AUTOSAR XML (schema 4-2-2)
package /STELLANTIS/EPT/SASWCs
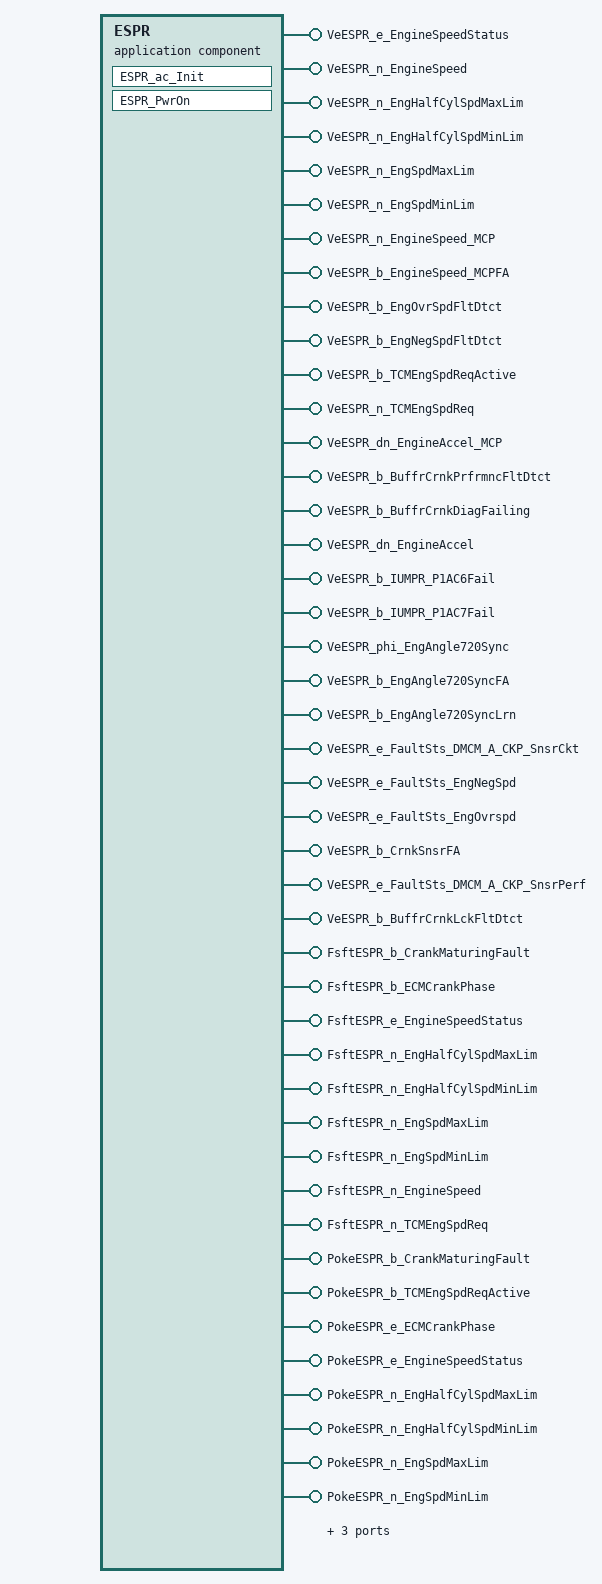
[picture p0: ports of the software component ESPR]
  application sw component type ESPR
    47 x provide port:
      VeESPR_e_EngineSpeedStatus: nonqueued-sender-com-spec{data-element=Value, init-value=CeESPR_e_EngSpdNormal}, provided-interface=VeESPR_e_EngineSpeedStatus
      VeESPR_n_EngineSpeed: nonqueued-sender-com-spec{data-element=Value, init-value=0}, provided-interface=VeESPR_n_EngineSpeed
      VeESPR_n_EngHalfCylSpdMaxLim: nonqueued-sender-com-spec{data-element=Value, init-value=0}, provided-interface=VeESPR_n_EngHalfCylSpdMaxLim
      VeESPR_n_EngHalfCylSpdMinLim: nonqueued-sender-com-spec{data-element=Value, init-value=0}, provided-interface=VeESPR_n_EngHalfCylSpdMinLim
      VeESPR_n_EngSpdMaxLim: nonqueued-sender-com-spec{data-element=Value, init-value=0}, provided-interface=VeESPR_n_EngSpdMaxLim
      VeESPR_n_EngSpdMinLim: nonqueued-sender-com-spec{data-element=Value, init-value=0}, provided-interface=VeESPR_n_EngSpdMinLim
      VeESPR_n_EngineSpeed_MCP: nonqueued-sender-com-spec{data-element=Value, init-value=0}, provided-interface=VeESPR_n_EngineSpeed_MCP
      VeESPR_b_EngineSpeed_MCPFA: nonqueued-sender-com-spec{data-element=Value, init-value=0}, provided-interface=VeESPR_b_EngineSpeed_MCPFA
      VeESPR_b_EngOvrSpdFltDtct: nonqueued-sender-com-spec{data-element=Value, init-value=0}, provided-interface=VeESPR_b_EngOvrSpdFltDtct
      VeESPR_b_EngNegSpdFltDtct: nonqueued-sender-com-spec{data-element=Value, init-value=0}, provided-interface=VeESPR_b_EngNegSpdFltDtct
      VeESPR_b_TCMEngSpdReqActive: nonqueued-sender-com-spec{data-element=Value, init-value=0}, provided-interface=VeESPR_b_TCMEngSpdReqActive
      VeESPR_n_TCMEngSpdReq: nonqueued-sender-com-spec{data-element=Value, init-value=0}, provided-interface=VeESPR_n_TCMEngSpdReq
      VeESPR_dn_EngineAccel_MCP: nonqueued-sender-com-spec{data-element=Value, init-value=0}, provided-interface=VeESPR_dn_EngineAccel_MCP
      VeESPR_b_BuffrCrnkPrfrmncFltDtct: nonqueued-sender-com-spec{data-element=Value, init-value=0}, provided-interface=VeESPR_b_BuffrCrnkPrfrmncFltDtct
      VeESPR_b_BuffrCrnkDiagFailing: nonqueued-sender-com-spec{data-element=Value, init-value=0}, provided-interface=VeESPR_b_BuffrCrnkDiagFailing
      VeESPR_dn_EngineAccel: nonqueued-sender-com-spec{data-element=Value, init-value=0}, provided-interface=VeESPR_dn_EngineAccel
      VeESPR_b_IUMPR_P1AC6Fail: nonqueued-sender-com-spec{data-element=Value, init-value=0}, provided-interface=VeESPR_b_IUMPR_P1AC6Fail
      VeESPR_b_IUMPR_P1AC7Fail: nonqueued-sender-com-spec{data-element=Value, init-value=0}, provided-interface=VeESPR_b_IUMPR_P1AC7Fail
      VeESPR_phi_EngAngle720Sync: nonqueued-sender-com-spec{data-element=Value, init-value=0}, provided-interface=VeESPR_phi_EngAngle720Sync
      VeESPR_b_EngAngle720SyncFA: nonqueued-sender-com-spec{data-element=Value, init-value=0}, provided-interface=VeESPR_b_EngAngle720SyncFA
      VeESPR_b_EngAngle720SyncLrn: nonqueued-sender-com-spec{data-element=Value, init-value=0}, provided-interface=VeESPR_b_EngAngle720SyncLrn
      VeESPR_e_FaultSts_DMCM_A_CKP_SnsrCkt: nonqueued-sender-com-spec{data-element=Value, init-value=CeDFIB_e_Init}, provided-interface=VeESPR_e_FaultSts_DMCM_A_CKP_SnsrCkt
      VeESPR_e_FaultSts_EngNegSpd: nonqueued-sender-com-spec{data-element=Value, init-value=CeDFIB_e_Init}, provided-interface=VeESPR_e_FaultSts_EngNegSpd
      VeESPR_e_FaultSts_EngOvrspd: nonqueued-sender-com-spec{data-element=Value, init-value=CeDFIB_e_Init}, provided-interface=VeESPR_e_FaultSts_EngOvrspd
      VeESPR_b_CrnkSnsrFA: nonqueued-sender-com-spec{data-element=Value, init-value=0}, provided-interface=VeESPR_b_CrnkSnsrFA
      VeESPR_e_FaultSts_DMCM_A_CKP_SnsrPerf: nonqueued-sender-com-spec{data-element=Value, init-value=CeDFIB_e_Init}, provided-interface=VeESPR_e_FaultSts_DMCM_A_CKP_SnsrPerf
      VeESPR_b_BuffrCrnkLckFltDtct: nonqueued-sender-com-spec{data-element=Value, init-value=0}, provided-interface=VeESPR_b_BuffrCrnkLckFltDtct
      FsftESPR_b_CrankMaturingFault: server-com-spec=FsftESPR_b_CrankMaturingFault, provided-interface=FsftESPR_b_CrankMaturingFault
      FsftESPR_b_ECMCrankPhase: server-com-spec=FsftESPR_b_ECMCrankPhase, provided-interface=FsftESPR_b_ECMCrankPhase
      FsftESPR_e_EngineSpeedStatus: server-com-spec=FsftESPR_e_EngineSpeedStatus, provided-interface=FsftESPR_e_EngineSpeedStatus
      FsftESPR_n_EngHalfCylSpdMaxLim: server-com-spec=FsftESPR_n_EngHalfCylSpdMaxLim, provided-interface=FsftESPR_n_EngHalfCylSpdMaxLim
      FsftESPR_n_EngHalfCylSpdMinLim: server-com-spec=FsftESPR_n_EngHalfCylSpdMinLim, provided-interface=FsftESPR_n_EngHalfCylSpdMinLim
      FsftESPR_n_EngSpdMaxLim: server-com-spec=FsftESPR_n_EngSpdMaxLim, provided-interface=FsftESPR_n_EngSpdMaxLim
      FsftESPR_n_EngSpdMinLim: server-com-spec=FsftESPR_n_EngSpdMinLim, provided-interface=FsftESPR_n_EngSpdMinLim
      FsftESPR_n_EngineSpeed: server-com-spec=FsftESPR_n_EngineSpeed, provided-interface=FsftESPR_n_EngineSpeed
      FsftESPR_n_TCMEngSpdReq: server-com-spec=FsftESPR_n_TCMEngSpdReq, provided-interface=FsftESPR_n_TCMEngSpdReq
      PokeESPR_b_CrankMaturingFault: server-com-spec{operation=PokeESPR_b_CrankMaturingFault, queue-length=1}, provided-interface=PokeESPR_b_CrankMaturingFault
      PokeESPR_b_TCMEngSpdReqActive: server-com-spec{operation=PokeESPR_b_TCMEngSpdReqActive, queue-length=1}, provided-interface=PokeESPR_b_TCMEngSpdReqActive
      PokeESPR_e_ECMCrankPhase: server-com-spec{operation=PokeESPR_e_ECMCrankPhase, queue-length=1}, provided-interface=PokeESPR_e_ECMCrankPhase
      PokeESPR_e_EngineSpeedStatus: server-com-spec{operation=PokeESPR_e_EngineSpeedStatus, queue-length=1}, provided-interface=PokeESPR_e_EngineSpeedStatus
      PokeESPR_n_EngHalfCylSpdMaxLim: server-com-spec{operation=PokeESPR_n_EngHalfCylSpdMaxLim, queue-length=1}, provided-interface=PokeESPR_n_EngHalfCylSpdMaxLim
      PokeESPR_n_EngHalfCylSpdMinLim: server-com-spec{operation=PokeESPR_n_EngHalfCylSpdMinLim, queue-length=1}, provided-interface=PokeESPR_n_EngHalfCylSpdMinLim
      PokeESPR_n_EngSpdMaxLim: server-com-spec{operation=PokeESPR_n_EngSpdMaxLim, queue-length=1}, provided-interface=PokeESPR_n_EngSpdMaxLim
      PokeESPR_n_EngSpdMinLim: server-com-spec{operation=PokeESPR_n_EngSpdMinLim, queue-length=1}, provided-interface=PokeESPR_n_EngSpdMinLim
      PokeESPR_n_EngineSpeed: server-com-spec{operation=PokeESPR_n_EngineSpeed, queue-length=1}, provided-interface=PokeESPR_n_EngineSpeed
      PokeESPR_n_EngineSpeed_MCP: server-com-spec{operation=PokeESPR_n_EngineSpeed_MCP, queue-length=1}, provided-interface=PokeESPR_n_EngineSpeed_MCP
      PokeESPR_n_TCMEngSpdReq: server-com-spec{operation=PokeESPR_n_TCMEngSpdReq, queue-length=1}, provided-interface=PokeESPR_n_TCMEngSpdReq
    behavior IB_ESPR: data-type-mapping=msADTtoIDTMapping, handle-termination-and-restart=NO-SUPPORT
      init event Event_ESPR_ac_Init: start-on-event=ESPR_ac_Init
      init event Event_PwrOn: start-on-event=ESPR_PwrOn
      runnable ESPR_ac_Init
        data-send-points:
          5 x access:
            OUT_VeESPR_e_EngineSpeedStatus_Value: accessed-variable=VeESPR_e_EngineSpeedStatus.Value
            OUT_VeESPR_e_FaultSts_DMCM_A_CKP_SnsrCkt_Value: accessed-variable=VeESPR_e_FaultSts_DMCM_A_CKP_SnsrCkt.Value
            OUT_VeESPR_e_FaultSts_EngNegSpd_Value: accessed-variable=VeESPR_e_FaultSts_EngNegSpd.Value
            OUT_VeESPR_e_FaultSts_EngOvrspd_Value: accessed-variable=VeESPR_e_FaultSts_EngOvrspd.Value
            OUT_VeESPR_e_FaultSts_DMCM_A_CKP_SnsrPerf_Value: accessed-variable=VeESPR_e_FaultSts_DMCM_A_CKP_SnsrPerf.Value
      runnable ESPR_PwrOn
        data-send-points:
          27 x access:
            OUT_VeESPR_n_EngHalfCylSpdMinLim_Value: accessed-variable=VeESPR_n_EngHalfCylSpdMinLim.Value
            OUT_VeESPR_n_TCMEngSpdReq_Value: accessed-variable=VeESPR_n_TCMEngSpdReq.Value
            OUT_VeESPR_n_EngHalfCylSpdMaxLim_Value: accessed-variable=VeESPR_n_EngHalfCylSpdMaxLim.Value
            OUT_VeESPR_n_EngSpdMaxLim_Value: accessed-variable=VeESPR_n_EngSpdMaxLim.Value
            OUT_VeESPR_n_EngSpdMinLim_Value: accessed-variable=VeESPR_n_EngSpdMinLim.Value
            OUT_VeESPR_e_EngineSpeedStatus_Value: accessed-variable=VeESPR_e_EngineSpeedStatus.Value
            OUT_VeESPR_n_EngineSpeed_Value: accessed-variable=VeESPR_n_EngineSpeed.Value
            OUT_VeESPR_b_EngAngle720SyncLrn_Value: accessed-variable=VeESPR_b_EngAngle720SyncLrn.Value
            OUT_VeESPR_dn_EngineAccel_MCP_Value: accessed-variable=VeESPR_dn_EngineAccel_MCP.Value
            OUT_VeESPR_b_BuffrCrnkPrfrmncFltDtct_Value: accessed-variable=VeESPR_b_BuffrCrnkPrfrmncFltDtct.Value
            OUT_VeESPR_b_EngineSpeed_MCPFA_Value: accessed-variable=VeESPR_b_EngineSpeed_MCPFA.Value
            OUT_VeESPR_b_IUMPR_P1AC6Fail_Value: accessed-variable=VeESPR_b_IUMPR_P1AC6Fail.Value
            OUT_VeESPR_b_IUMPR_P1AC7Fail_Value: accessed-variable=VeESPR_b_IUMPR_P1AC7Fail.Value
            OUT_VeESPR_b_EngOvrSpdFltDtct_Value: accessed-variable=VeESPR_b_EngOvrSpdFltDtct.Value
            OUT_VeESPR_b_EngNegSpdFltDtct_Value: accessed-variable=VeESPR_b_EngNegSpdFltDtct.Value
            OUT_VeESPR_n_EngineSpeed_MCP_Value: accessed-variable=VeESPR_n_EngineSpeed_MCP.Value
            OUT_VeESPR_b_TCMEngSpdReqActive_Value: accessed-variable=VeESPR_b_TCMEngSpdReqActive.Value
            OUT_VeESPR_b_BuffrCrnkDiagFailing_Value: accessed-variable=VeESPR_b_BuffrCrnkDiagFailing.Value
            OUT_VeESPR_dn_EngineAccel_Value: accessed-variable=VeESPR_dn_EngineAccel.Value
            OUT_VeESPR_phi_EngAngle720Sync_Value: accessed-variable=VeESPR_phi_EngAngle720Sync.Value
            OUT_VeESPR_b_EngAngle720SyncFA_Value: accessed-variable=VeESPR_b_EngAngle720SyncFA.Value
            OUT_VeESPR_e_FaultSts_DMCM_A_CKP_SnsrCkt_Value: accessed-variable=VeESPR_e_FaultSts_DMCM_A_CKP_SnsrCkt.Value
            OUT_VeESPR_e_FaultSts_EngNegSpd_Value: accessed-variable=VeESPR_e_FaultSts_EngNegSpd.Value
            OUT_VeESPR_e_FaultSts_EngOvrspd_Value: accessed-variable=VeESPR_e_FaultSts_EngOvrspd.Value
            OUT_VeESPR_b_CrnkSnsrFA_Value: accessed-variable=VeESPR_b_CrnkSnsrFA.Value
            OUT_VeESPR_e_FaultSts_DMCM_A_CKP_SnsrPerf_Value: accessed-variable=VeESPR_e_FaultSts_DMCM_A_CKP_SnsrPerf.Value
            OUT_VeESPR_b_BuffrCrnkLckFltDtct_Value: accessed-variable=VeESPR_b_BuffrCrnkLckFltDtct.Value
      5 x variation point proxy, all with category=CONDITION, condition-access=0:
        Variant_ESPR_{1..5}
